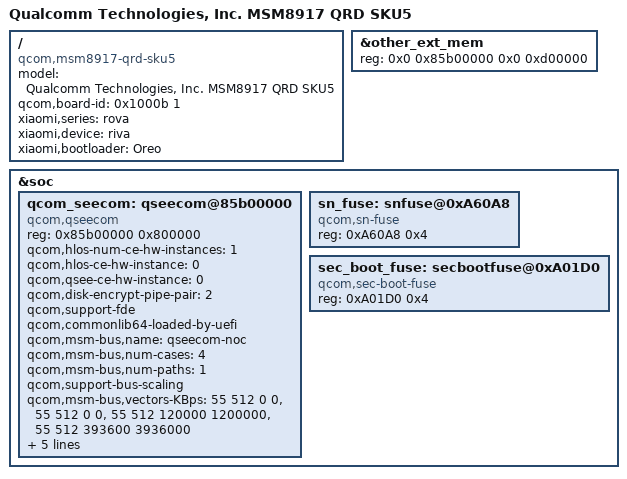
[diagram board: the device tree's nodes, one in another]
/*
 * Copyright (c) 2016, The Linux Foundation. All rights reserved.
 * Copyright (C) 2019 XiaoMi, Inc.
 *
 * This program is free software; you can redistribute it and/or modify
 * it under the terms of the GNU General Public License version 2 and
 * only version 2 as published by the Free Software Foundation.
 *
 * This program is distributed in the hope that it will be useful,
 * but WITHOUT ANY WARRANTY; without even the implied warranty of
 * MERCHANTABILITY or FITNESS FOR A PARTICULAR PURPOSE.  See the
 * GNU General Public License for more details.
 */

/dts-v1/;

#include "msm8917.dtsi"
#include "msm8917-qrd.dtsi"
#include "msm8937-mdss-panels.dtsi"
#include "msm8917-audio.dtsi"

#include "xiaomi/xiaomi.dtsi"
#include "xiaomi/rova/rova-overlay.dtsi"
#include "xiaomi/rova/riva/riva-overlay.dtsi"

/ {
	model = "Qualcomm Technologies, Inc. MSM8917 QRD SKU5";
	compatible = "qcom,msm8917-qrd-sku5", "qcom,msm8917-qrd",
		   "qcom,msm8917", "qcom,qrd";
	qcom,board-id= <0x1000b 1>;

	xiaomi,series = "rova";
	xiaomi,device = "riva";

	xiaomi,bootloader = "Oreo";
};

&other_ext_mem {
	reg = <0x0 0x85b00000 0x0 0xd00000>;
};

&soc {
	/delete-node/ qseecom@84a00000;
	qcom_seecom: qseecom@85b00000 {
		compatible = "qcom,qseecom";
			reg = <0x85b00000 0x800000>;
		reg-names = "secapp-region";
		qcom,hlos-num-ce-hw-instances = <1>;
		qcom,hlos-ce-hw-instance = <0>;
		qcom,qsee-ce-hw-instance = <0>;
		qcom,disk-encrypt-pipe-pair = <2>;
		qcom,support-fde;
		qcom,commonlib64-loaded-by-uefi;
		qcom,msm-bus,name = "qseecom-noc";
		qcom,msm-bus,num-cases = <4>;
		qcom,msm-bus,num-paths = <1>;
		qcom,support-bus-scaling;
		qcom,msm-bus,vectors-KBps =
			<55 512 0 0>,
			<55 512 0 0>,
			<55 512 120000 1200000>,
			<55 512 393600 3936000>;
		clocks = <&clock_gcc clk_crypto_clk_src>,
			 <&clock_gcc clk_gcc_crypto_clk>,
			 <&clock_gcc clk_gcc_crypto_ahb_clk>,
			 <&clock_gcc clk_gcc_crypto_axi_clk>;
		clock-names = "core_clk_src", "core_clk",
				"iface_clk", "bus_clk";
		qcom,ce-opp-freq = <100000000>;
	};

	/delete-node/ snfuse@0xa0128;
	/delete-node/ secbootfuse@0xa41d0;

	sn_fuse: snfuse@0xA60A8 {
		compatible = "qcom,sn-fuse";
		reg = <0xA60A8 0x4>;
		reg-names = "sn-base";
	};

	sec_boot_fuse: secbootfuse@0xA01D0 {
		compatible = "qcom,sec-boot-fuse";
		reg = <0xA01D0 0x4>;
		reg-names = "sec-boot-base";
	};
};
